# AST1080 register map
File version: 1.0
CPU: CM4 r0p1, little endian, MPU, FPU, 4 interrupt priority bits, 256 interrupts
Registers are 32-bit, read-write, reset 0x0 unless marked. A register's access mark holds for its fields unless they carry their own. Offsets are from the block's base; [hi:lo] are bit positions; {n}, {i} and the like mark numbered series.

## spi
Base 0x74000000
Same registers: spi1 0x74010000, spi2 0x74020000
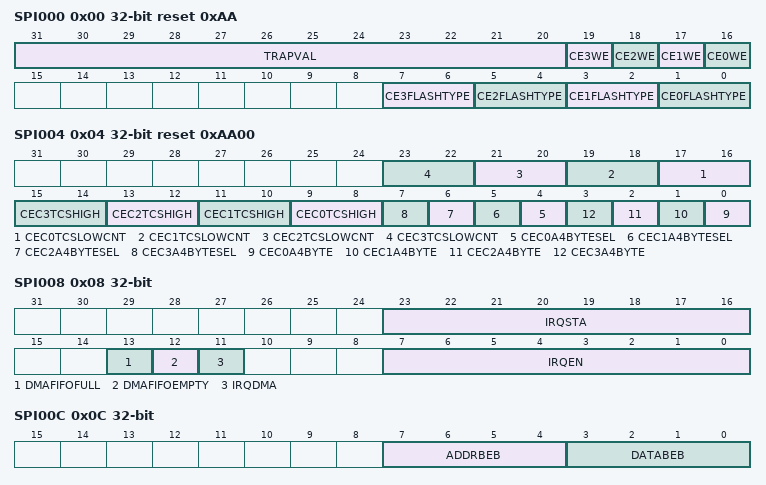
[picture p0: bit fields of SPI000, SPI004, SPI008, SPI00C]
0x00 SPI000 reset 0xAA — SPI Flash Configuration Register
  [31:20] TRAPVAL ro, [n+16] CE{n}WE (n=0..3), [2n+1:2n] CE{n}FLASHTYPE ro (n=0..3)
0x04 SPI004 reset 0xAA00 — CE Control Register
  [2n+17:2n+16] CEC{n}TCSLOWCNT (n=0..3), [2n+9:2n+8] CEC{n}TCSHIGH (n=0..3), [n+4] CEC{n}A4BYTESEL (n=0..3), [n] CEC{n}A4BYTE (n=0..3)
0x08 SPI008 — Interrupt Control and Status Register
  [23:16] IRQSTA, [13] DMAFIFOFULL ro, [12] DMAFIFOEMPTY ro, [11] IRQDMA ro, [7:0] IRQEN
0x0C SPI00C — Command Control Register
  [7:4] ADDRBEB, [3:0] DATABEB
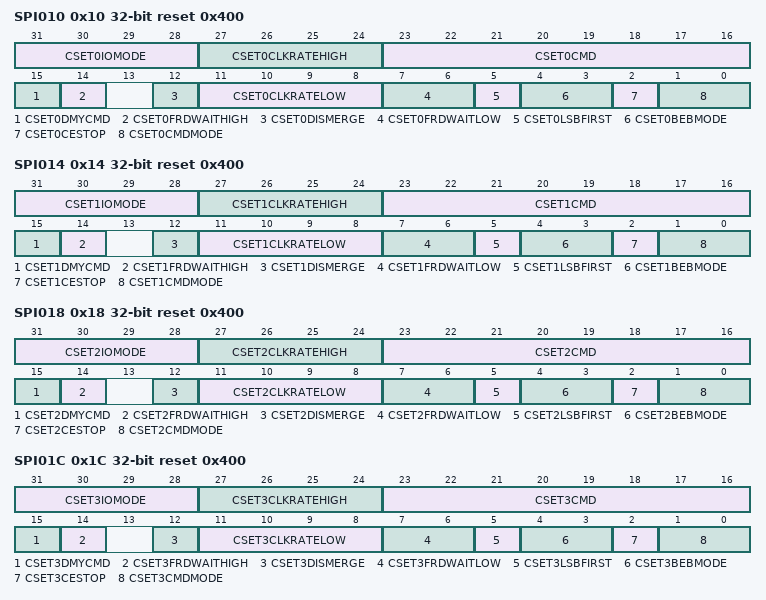
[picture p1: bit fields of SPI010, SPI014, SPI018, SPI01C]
0x10 SPI010 reset 0x400 — CE0 Control Register
  [31:28] CSET0IOMODE, [27:24] CSET0CLKRATEHIGH, [23:16] CSET0CMD, [15] CSET0DMYCMD, [14] CSET0FRDWAITHIGH, [12] CSET0DISMERGE, [11:8] CSET0CLKRATELOW, [7:6] CSET0FRDWAITLOW, [5] CSET0LSBFIRST, [4:3] CSET0BEBMODE, [2] CSET0CESTOP, [1:0] CSET0CMDMODE
0x14 SPI014 reset 0x400 — CE1 Control Register
  [31:28] CSET1IOMODE, [27:24] CSET1CLKRATEHIGH, [23:16] CSET1CMD, [15] CSET1DMYCMD, [14] CSET1FRDWAITHIGH, [12] CSET1DISMERGE, [11:8] CSET1CLKRATELOW, [7:6] CSET1FRDWAITLOW, [5] CSET1LSBFIRST, [4:3] CSET1BEBMODE, [2] CSET1CESTOP, [1:0] CSET1CMDMODE
0x18 SPI018 reset 0x400 — CE2 Control Register
  [31:28] CSET2IOMODE, [27:24] CSET2CLKRATEHIGH, [23:16] CSET2CMD, [15] CSET2DMYCMD, [14] CSET2FRDWAITHIGH, [12] CSET2DISMERGE, [11:8] CSET2CLKRATELOW, [7:6] CSET2FRDWAITLOW, [5] CSET2LSBFIRST, [4:3] CSET2BEBMODE, [2] CSET2CESTOP, [1:0] CSET2CMDMODE
0x1C SPI01C reset 0x400 — CE3 Control Register
  [31:28] CSET3IOMODE, [27:24] CSET3CLKRATEHIGH, [23:16] CSET3CMD, [15] CSET3DMYCMD, [14] CSET3FRDWAITHIGH, [12] CSET3DISMERGE, [11:8] CSET3CLKRATELOW, [7:6] CSET3FRDWAITLOW, [5] CSET3LSBFIRST, [4:3] CSET3BEBMODE, [2] CSET3CESTOP, [1:0] CSET3CMDMODE
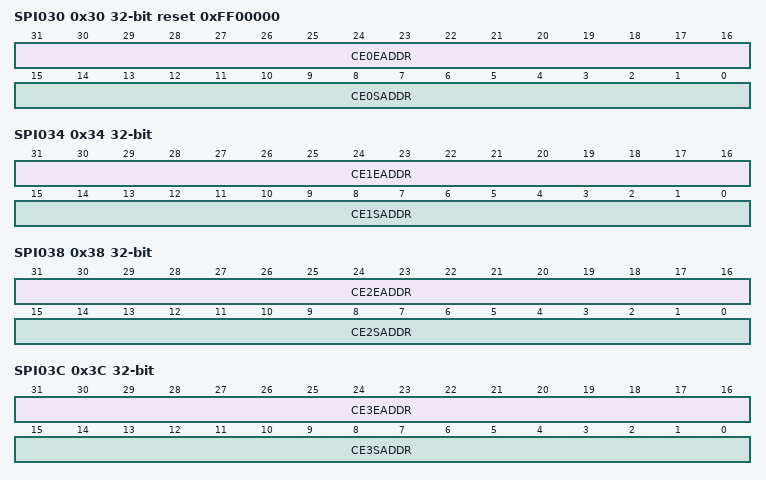
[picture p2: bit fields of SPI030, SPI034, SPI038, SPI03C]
0x30 SPI030 reset 0xFF00000 — CE0 Address Decoding Range Register
  [31:16] CE0EADDR, [15:0] CE0SADDR
0x34 SPI034 — CE1 Address Decoding Range Register
  [31:16] CE1EADDR, [15:0] CE1SADDR
0x38 SPI038 — CE2 Address Decoding Range Register
  [31:16] CE2EADDR, [15:0] CE2SADDR
0x3C SPI03C — CE3 Address Decoding Range Register
  [31:16] CE3EADDR, [15:0] CE3SADDR
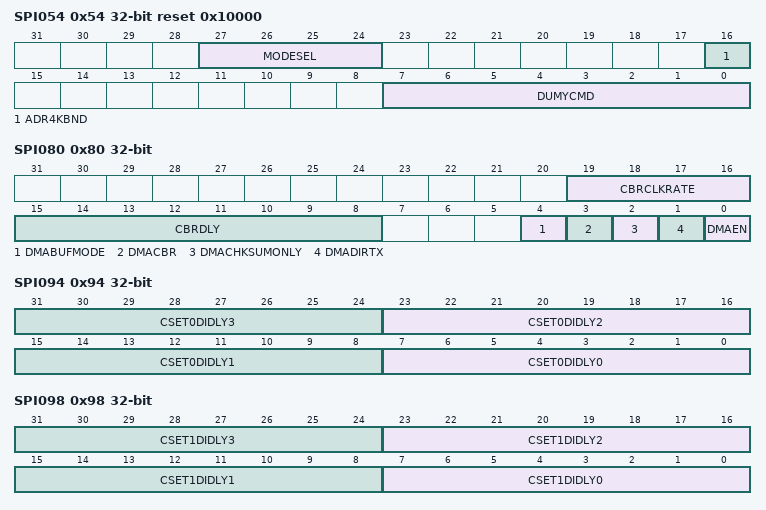
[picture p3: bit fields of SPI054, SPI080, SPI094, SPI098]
0x54 SPI054 reset 0x10000 — SPI Dummy Cycle Data Register
  [27:24] MODESEL, [16] ADR4KBND, [7:0] DUMYCMD
0x7C SPI07C — DMA DRAM Side Address High Part
  [7:0] DMAROHI
0x80 SPI080 — DMA Control/Status Register
  [19:16] CBRCLKRATE, [15:8] CBRDLY, [4] DMABUFMODE, [3] DMACBR, [2] DMACHKSUMONLY, [1] DMADIRTX, [0] DMAEN
0x84 SPI084 — DMA Flash Side Address
  [31:0] DMARI
0x88 SPI088 — DMA DRAM Side Address
  [31:0] DMARO
0x8C SPI08C — DMA Length Register
  [24:0] DMALEN
0x90 SPI090 — CheckSum Calculation Result
  [31:0] DMACHKSUM ro
0x94 SPI094 — CE0 SPI Flash Read Timing Compensation
  [8n+7:8n] CSET0DIDLY{n} (n=0..3)
0x98 SPI098 — CE1 SPI Flash Read Timing Compensation
  [8n+7:8n] CSET1DIDLY{n} (n=0..3)
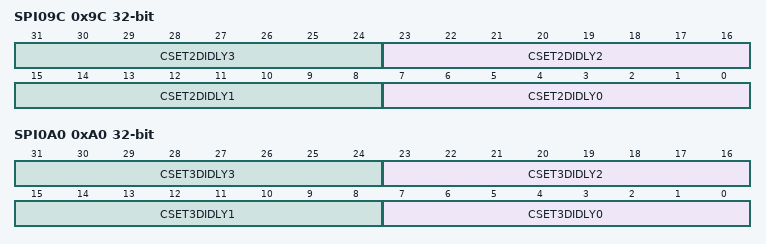
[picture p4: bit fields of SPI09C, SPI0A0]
0x9C SPI09C — CE2 SPI Flash Read Timing Compensation
  [8n+7:8n] CSET2DIDLY{n} (n=0..3)
0xA0 SPI0A0 — CE3 SPI Flash Read Timing Compensation
  [8n+7:8n] CSET3DIDLY{n} (n=0..3)
0x1C0 SPI1C0 — reserved
  [6:0] DMAFFLEN
0x1E0 SPI1E0 — SPI Engine Status report
  [31:0] SPISTATUS ro
0x1E4 SPI1E4 — SPI Data in monitor
  [31:0] SPIDIMNT ro
0x1E8 SPI1E8 — SPI SOC RESET information
  [0] SOCRST ro
0x1F0 SPI1F0 — SPI Write lock Status for Configure Write until SRST\#
  [31:0] WLOCK0
0x1F4 SPI1F4 — SPI Write lock Status when SOC RESET is coming
  [31:0] WLOCK1
0x1F8 SPI1F8 — SPI Write lock Status for Configure Write until soc reset
  [31:0] WLOCK2
0x1FC SPI1FC — SPI Write lock status for Configure Write
  [31:0] WLOCKX ro

## sgpio
Base 0x74C0C000
Same registers: sgpio1 0x74C0D000
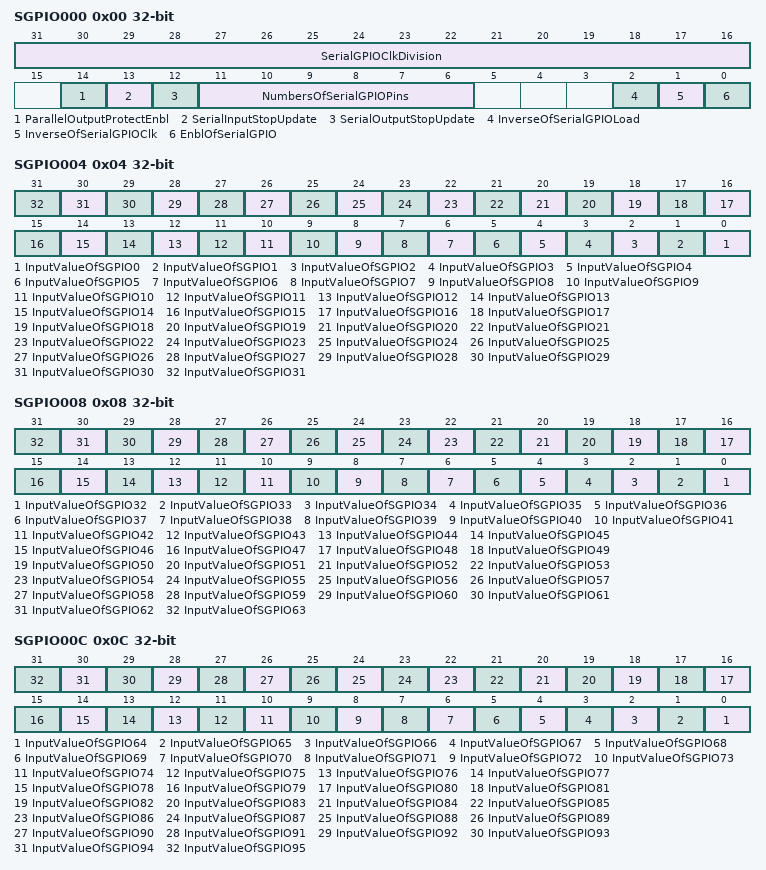
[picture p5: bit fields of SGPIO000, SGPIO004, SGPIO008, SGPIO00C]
0x00 SGPIO000 — Serial GPIO Configuration Register
  [31:16] SerialGPIOClkDivision — Serial GPIO clock division
  [14] ParallelOutputProtectEnbl — Parallel output protect enable
  [13] SerialInputStopUpdate
  [12] SerialOutputStopUpdate
  [11:6] NumbersOfSerialGPIOPins
  [2] InverseOfSerialGPIOLoad
    0=Not_Inverse; 1=Inverse
  [1] InverseOfSerialGPIOClk — Inverse of Serial GPIO clock
    0=Not_Inverse; 1=Inverse
  [0] EnblOfSerialGPIO — Enable of Serial GPIO
    0=Disable; 1=Enable
0x04 SGPIO004 — Debug Serial In Register \#0
  [n] InputValueOfSGPIO{n} ro (n=0..31)
0x08 SGPIO008 — Debug Serial In Register \#1
  [n-32] InputValueOfSGPIO{n} ro (n=32..63)
0x0C SGPIO00C — Debug Serial In Register \#2
  [n-64] InputValueOfSGPIO{n} ro (n=64..95)
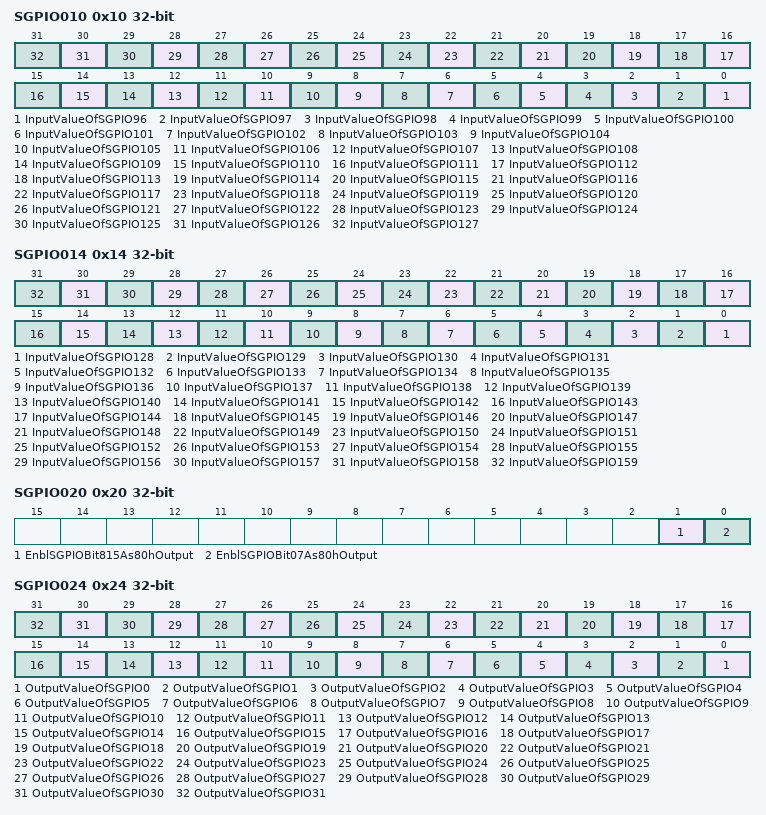
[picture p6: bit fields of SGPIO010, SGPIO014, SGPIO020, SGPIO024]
0x10 SGPIO010 — Debug Serial In Register \#3
  [n-96] InputValueOfSGPIO{n} ro (n=96..127)
0x14 SGPIO014 — Debug Serial In Register \#4
  [n-128] InputValueOfSGPIO{n} ro (n=128..159)
0x20 SGPIO020 — 80h Enable Register
  [1] EnblSGPIOBit815As80hOutput — Enable SGPIO bit 8~15 as 80h output
  [0] EnblSGPIOBit07As80hOutput — Enable SGPIO bit 0~7 as 80h output
0x24 SGPIO024 — Debug Serial Out Register \#0
  [n] OutputValueOfSGPIO{n} ro (n=0..31)
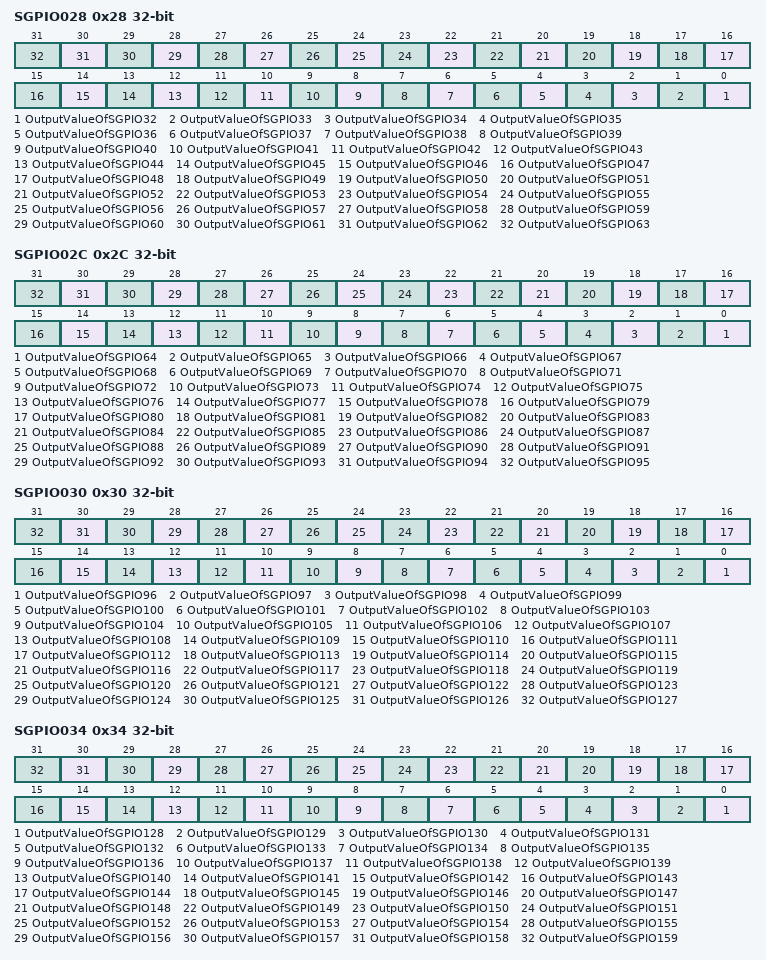
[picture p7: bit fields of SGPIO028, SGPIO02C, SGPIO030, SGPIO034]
0x28 SGPIO028 — Debug Serial Out Register \#1
  [n-32] OutputValueOfSGPIO{n} ro (n=32..63)
0x2C SGPIO02C — Debug Serial In Register \#2
  [n-64] OutputValueOfSGPIO{n} ro (n=64..95)
0x30 SGPIO030 — Debug Serial In Register \#3
  [n-96] OutputValueOfSGPIO{n} ro (n=96..127)
0x34 SGPIO034 — Debug Serial Out Register \#4
  [n-128] OutputValueOfSGPIO{n} ro (n=128..159)
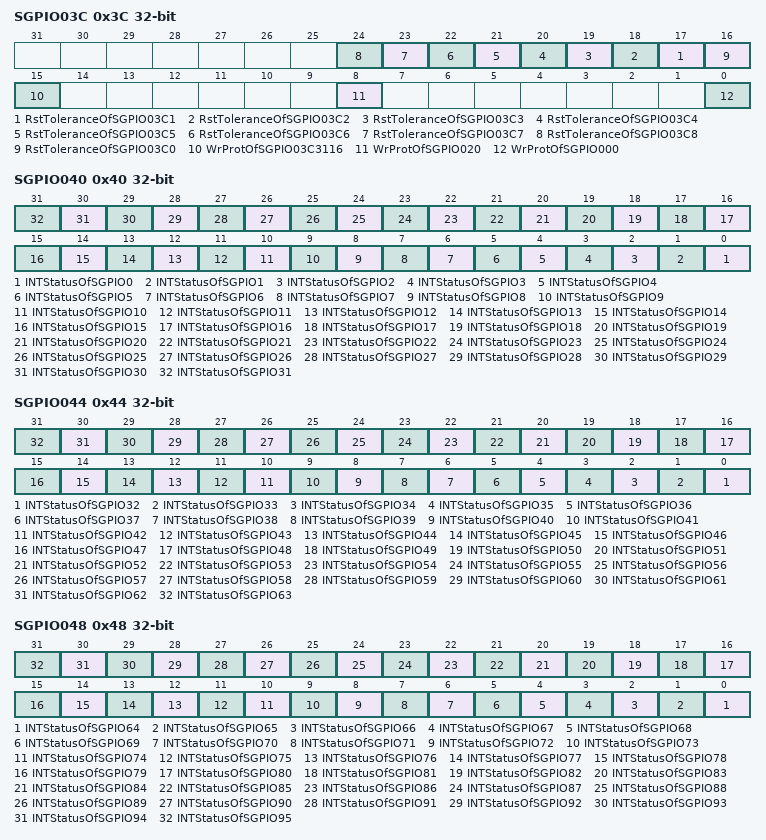
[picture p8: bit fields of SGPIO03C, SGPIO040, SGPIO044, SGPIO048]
0x3C SGPIO03C — Write Protection Register
  [n+16] RstToleranceOfSGPIO03C{n} (n=1..8) — Reset Tolerance of SGPIO03C[{n}]
  [16] RstToleranceOfSGPIO03C0 — Reset Tolerance of SGPIO03C[0]
    0=SRST; 1=WDT_Reset
  [15] WrProtOfSGPIO03C3116 — Write Protection of SGPIO03C[31:16]
  [8] WrProtOfSGPIO020 — Write Protection of SGPIO020
  [0] WrProtOfSGPIO000 — Write Protection of SGPIO000
0x40 SGPIO040 — Interrupt Status Register \#0
  [n] INTStatusOfSGPIO{n} ro (n=0..31) — Interrupt Status of SGPIO_{n}
0x44 SGPIO044 — Interrupt Status Register \#1
  [n-32] INTStatusOfSGPIO{n} ro (n=32..63) — Interrupt Status of SGPIO_{n}
0x48 SGPIO048 — Interrupt Status Register \#2
  [n-64] INTStatusOfSGPIO{n} ro (n=64..95) — Interrupt Status of SGPIO_{n}
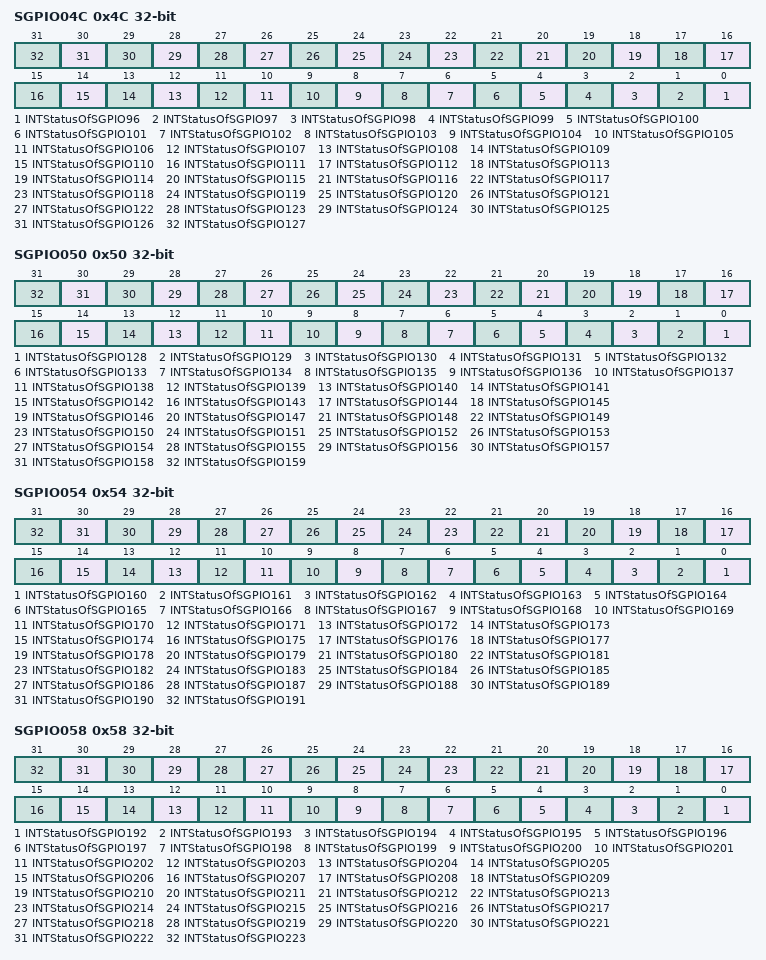
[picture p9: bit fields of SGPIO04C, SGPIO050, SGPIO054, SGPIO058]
0x4C SGPIO04C — Interrupt Status Register \#3
  [n-96] INTStatusOfSGPIO{n} ro (n=96..127) — Interrupt Status of SGPIO_{n}
0x50 SGPIO050 — Interrupt Status Register \#4
  [n-128] INTStatusOfSGPIO{n} ro (n=128..159) — Interrupt Status of SGPIO_{n}
0x54 SGPIO054 — Interrupt Status Register \#5
  [n-160] INTStatusOfSGPIO{n} ro (n=160..191) — Interrupt Status of SGPIO_{n}
0x58 SGPIO058 — Interrupt Status Register \#6
  [n-192] INTStatusOfSGPIO{n} ro (n=192..223) — Interrupt Status of SGPIO_{n}
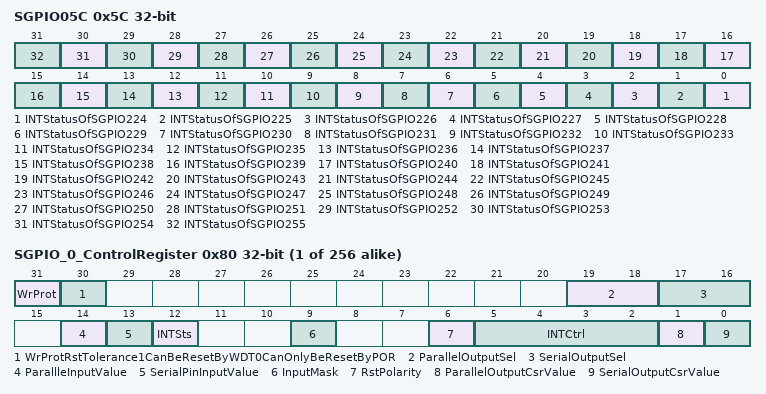
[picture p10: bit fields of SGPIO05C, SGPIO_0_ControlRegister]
0x5C SGPIO05C — Interrupt Status Register \#7
  [n-224] INTStatusOfSGPIO{n} ro (n=224..255) — Interrupt Status of SGPIO_{n}
{0x80+4i} SGPIO_{i}_ControlRegister (i=0..255) — SGPIO\_N Control Register N=0~255
  [31] WrProt — Write protection
  [30] WrProtRstTolerance1CanBeResetByWDT0CanOnlyBeResetByPOR — Write protection reset tolerance. 1: can be reset by WDT, 0: can only be reset by POR.
  [19:18] ParallelOutputSel — Parallel output selection
  [17:16] SerialOutputSel — Serial output selection
  [14] ParallleInputValue
  [13] SerialPinInputValue
  [12] INTSts — Interrupt status
  [9] InputMask
  [6] RstPolarity — Reset Polarity
  [5:2] INTCtrl — Interrupt control
  [1] ParallelOutputCsrValue
  [0] SerialOutputCsrValue
